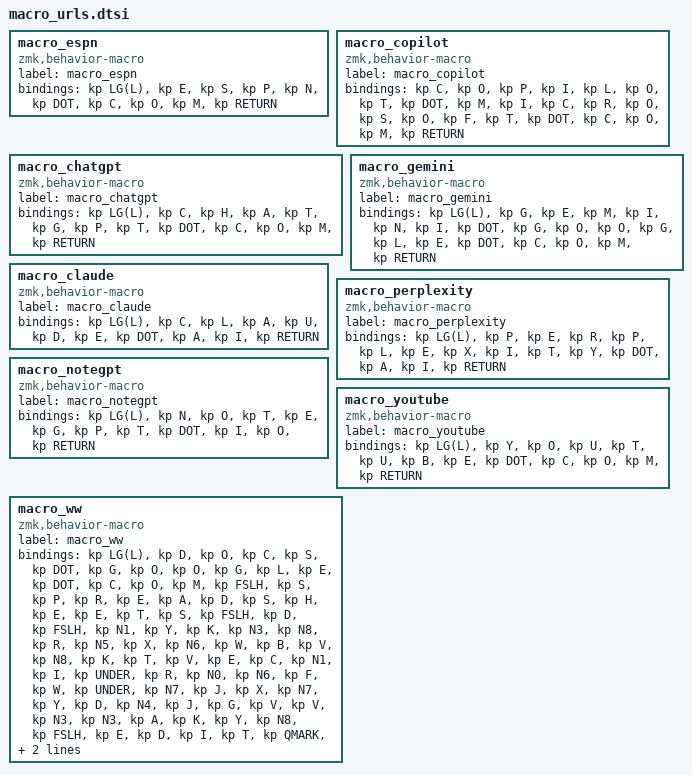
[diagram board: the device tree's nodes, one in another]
macro_espn: macro_espn{
compatible = "zmk,behavior-macro";
label = "macro_espn";
#binding-cells = <0>;
bindings = <&kp LG(L)>, <&kp E>, <&kp S>, <&kp P>, <&kp N>, <&kp DOT>, <&kp C>, <&kp O>, <&kp M>, <&kp RETURN>;
};

/* https://copilot.microsoft.com/ */
macro_copilot: macro_copilot {
    compatible = "zmk,behavior-macro";
    label = "macro_copilot";
    #binding-cells = <0>;
    bindings = <&kp C &kp O &kp P &kp I &kp L &kp O &kp T &kp DOT &kp M &kp I &kp C &kp R &kp O &kp S &kp O &kp F &kp T &kp DOT &kp C &kp O &kp M>, <&kp RETURN>;
};

/* https://chatgpt.com */
macro_chatgpt: macro_chatgpt {
    compatible = "zmk,behavior-macro";
    label = "macro_chatgpt";
    #binding-cells = <0>;
    bindings = <&kp LG(L)>, <&kp C &kp H &kp A &kp T &kp G &kp P &kp T &kp DOT &kp C &kp O &kp M>, <&kp RETURN>;
};

/* https://gemini.google.com */
macro_gemini: macro_gemini {
    compatible = "zmk,behavior-macro";
    label = "macro_gemini";
    #binding-cells = <0>;
    bindings = <&kp LG(L)>, <&kp G &kp E &kp M &kp I &kp N &kp I &kp DOT &kp G &kp O &kp O &kp G &kp L &kp E &kp DOT &kp C &kp O &kp M>, <&kp RETURN>;
};

/* https://claude.ai */
macro_claude: macro_claude {
    compatible = "zmk,behavior-macro";
    label = "macro_claude";
    #binding-cells = <0>;
    bindings = <&kp LG(L)>, <&kp C &kp L &kp A &kp U &kp D &kp E &kp DOT &kp A &kp I>, <&kp RETURN>;
};

/* https://www.perplexity.ai */
macro_perplexity: macro_perplexity {
    compatible = "zmk,behavior-macro";
    label = "macro_perplexity";
    #binding-cells = <0>;
    bindings = <&kp LG(L)>, <&kp P &kp E &kp R &kp P &kp L &kp E &kp X &kp I &kp T &kp Y &kp DOT &kp A &kp I>, <&kp RETURN>;
};

/* https://notegpt.io */
macro_notegpt: macro_notegpt {
    compatible = "zmk,behavior-macro";
    label = "macro_notegpt";
    #binding-cells = <0>;
    bindings = <&kp LG(L)>, <&kp N &kp O &kp T &kp E &kp G &kp P &kp T &kp DOT &kp I &kp O>, <&kp RETURN>;
};

/* https://youtube.com */
macro_youtube: macro_youtube {
    compatible = "zmk,behavior-macro";
    label = "macro_youtube";
    #binding-cells = <0>;
    bindings = <&kp LG(L)>, <&kp Y &kp O &kp U &kp T &kp U &kp B &kp E &kp DOT &kp C &kp O &kp M>, <&kp RETURN>;
};

/* weight tracking link */
/* https://docs.google.com/spreadsheets/d/1Yk38r5X6wBV8kTVEC1I_R06Fw_7jx7yD4JGvv33aky8/edit?usp=sharing */
macro_ww: macro_ww {
    compatible = "zmk,behavior-macro";
    label = "macro_ww";
    #binding-cells = <0>;
    bindings = <&kp LG(L)>, <&kp D &kp O &kp C &kp S &kp DOT &kp G &kp O &kp O &kp G &kp L &kp E &kp DOT &kp C &kp O &kp M &kp FSLH &kp S &kp P &kp R &kp E &kp A &kp D &kp S &kp H &kp E &kp E &kp T &kp S &kp FSLH &kp D &kp FSLH &kp N1 &kp Y &kp K &kp N3 &kp N8 &kp R &kp N5 &kp X &kp N6 &kp W &kp B &kp V &kp N8 &kp K &kp T &kp V &kp E &kp C &kp N1 &kp I &kp UNDER &kp R &kp N0 &kp N6 &kp F &kp W &kp UNDER &kp N7 &kp J &kp X &kp N7 &kp Y &kp D &kp N4 &kp J &kp G &kp V &kp V &kp N3 &kp N3 &kp A &kp K &kp Y &kp N8 &kp FSLH &kp E &kp D &kp I &kp T &kp QMARK &kp U &kp S &kp P &kp EQUAL &kp S &kp H &kp A &kp R &kp I &kp N &kp G>, <&kp RETURN>;
};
